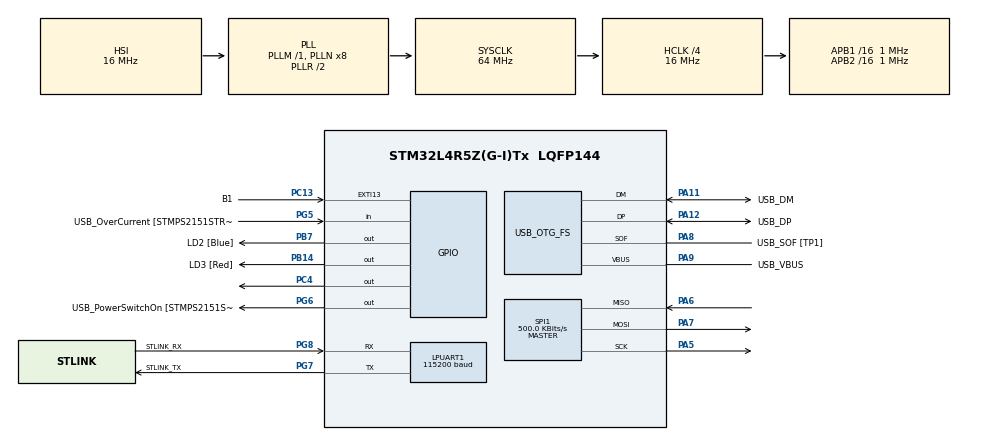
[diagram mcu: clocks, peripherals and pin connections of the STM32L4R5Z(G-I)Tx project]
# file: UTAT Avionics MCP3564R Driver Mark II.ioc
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LPUART1.BaudRate=115200
LPUART1.WordLength=UART_WORDLENGTH_8B
Mcu.Family=STM32L4
Mcu.Name=STM32L4R5Z(G-I)Tx
Mcu.Package=LQFP144
NVIC.PriorityGroup=NVIC_PRIORITYGROUP_4
PA10.GPIO_Label=USB_ID
PA10.Signal=USB_OTG_FS_ID
PA11.GPIO_Label=USB_DM
PA11.Mode=Device_Only
PA11.Signal=USB_OTG_FS_DM
PA12.GPIO_Label=USB_DP
PA12.Mode=Device_Only
PA12.Signal=USB_OTG_FS_DP
PA13\ (JTMS/SWDIO).GPIO_Label=TMS
PA13\ (JTMS/SWDIO).Mode=Trace_Asynchronous_SW
PA13\ (JTMS/SWDIO).Signal=SYS_JTMS-SWDIO
PA14\ (JTCK/SWCLK).GPIO_Label=TCK
PA14\ (JTCK/SWCLK).Mode=Trace_Asynchronous_SW
PA14\ (JTCK/SWCLK).Signal=SYS_JTCK-SWCLK
PA5.Mode=Full_Duplex_Master
PA5.Signal=SPI1_SCK
PA6.Mode=Full_Duplex_Master
PA6.Signal=SPI1_MISO
PA7.Mode=Full_Duplex_Master
PA7.Signal=SPI1_MOSI
PA8.GPIO_Label=USB_SOF [TP1]
PA8.Mode=Activate_SOF_FS
PA8.Signal=USB_OTG_FS_SOF
PA9.GPIO_Label=USB_VBUS
PA9.Mode=Activate_VBUS
PA9.Signal=USB_OTG_FS_VBUS
PB14.GPIO_Label=LD3 [Red]
PB14.Signal=GPIO_Output
PB3\ (JTDO/TRACESWO).GPIO_Label=SWO
PB3\ (JTDO/TRACESWO).Mode=Trace_Asynchronous_SW
PB3\ (JTDO/TRACESWO).Signal=SYS_JTDO-SWO
PB7.GPIO_Label=LD2 [Blue]
PB7.Signal=GPIO_Output
PC13.GPIO_Label=B1
PC13.Signal=GPXTI13
PC14-OSC32_IN\ (PC14).Mode=LSE-External-Oscillator
PC14-OSC32_IN\ (PC14).Signal=RCC_OSC32_IN
PC15-OSC32_OUT\ (PC15).Mode=LSE-External-Oscillator
PC15-OSC32_OUT\ (PC15).Signal=RCC_OSC32_OUT
PC4.Signal=GPIO_Output
PD8.GPIO_Label=STLK_RX [STM32F103CBT6_PA3]
PD8.Signal=USART3_TX
PD9.GPIO_Label=STLK_TX [STM32F103CBT6_PA2]
PD9.Signal=USART3_RX
PG5.GPIO_Label=USB_OverCurrent [STMPS2151STR_FAULT]
PG5.Signal=GPIO_Input
PG6.GPIO_Label=USB_PowerSwitchOn [STMPS2151STR_EN]
PG6.Signal=GPIO_Output
PG7.GPIO_Label=STLINK_TX
PG7.Mode=Asynchronous
PG7.Signal=LPUART1_TX
PG8.GPIO_Label=STLINK_RX
PG8.Mode=Asynchronous
PG8.Signal=LPUART1_RX
PH0-OSC_IN\ (PH0).Signal=RCC_OSC_IN
PH1-OSC_OUT\ (PH1).Signal=RCC_OSC_OUT
ProjectManager.HeapSize=0x200
ProjectManager.StackSize=0x400
ProjectManager.TargetToolchain=STM32CubeIDE
RCC.48MHZClocksFreq_Value=24000000
RCC.ADCFreq_Value=96000000
RCC.AHBCLKDivider=RCC_SYSCLK_DIV4
RCC.AHBFreq_Value=16000000
RCC.APB1CLKDivider=RCC_HCLK_DIV16
RCC.APB1Freq_Value=1000000
RCC.APB1TimFreq_Value=2000000
RCC.APB2CLKDivider=RCC_HCLK_DIV16
RCC.APB2Freq_Value=1000000
RCC.APB2TimFreq_Value=2000000
RCC.CK48CLockSelection=RCC_USBCLKSOURCE_HSI48
RCC.CortexFreq_Value=16000000
RCC.HCLKFreq_Value=16000000
RCC.HSE_VALUE=8000000
RCC.HSI48_VALUE=48000000
RCC.HSI_VALUE=16000000
RCC.MSI_VALUE=4000000
RCC.PLLMUL=RCC_PLL_MUL9
RCC.PLLSAI1N=12
RCC.PLLSourceVirtual=RCC_PLLSOURCE_HSI
RCC.PRESCALERUSB=RCC_USBCLKSOURCE_PLL_DIV1_5
RCC.SYSCLKFreq_VALUE=64000000
RCC.SYSCLKSource=RCC_SYSCLKSOURCE_PLLCLK
RCC.SYSCLKSourceVirtual=RCC_SYSCLKSOURCE_PLLCLK
RCC.USBFreq_Value=48000000
RCC.VCOOutputFreq_Value=128000000
SPI1.CalculateBaudRate=500.0 KBits/s
SPI1.DataSize=SPI_DATASIZE_8BIT
SPI1.Direction=SPI_DIRECTION_2LINES
SPI1.Mode=SPI_MODE_MASTER
SPI1.VirtualType=VM_MASTER
USB_OTG_FS.VirtualMode=Device_Only
board=NUCLEO-L4R5ZI

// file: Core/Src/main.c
/* USER CODE BEGIN Header */
/**
  ******************************************************************************
  * @file           : main.c
  * @brief          : Main program body
  ******************************************************************************
  * @attention
  *
  * Copyright (c) 2025 STMicroelectronics.
  * All rights reserved.
  *
  * This software is licensed under terms that can be found in the LICENSE file
  * in the root directory of this software component.
  * If no LICENSE file comes with this software, it is provided AS-IS.
  *
  ******************************************************************************
  */
/* USER CODE END Header */
#include "main.h"

/* USER CODE BEGIN Includes */
#include "MCP3564R.h"
#include <stdio.h>
#include <string.h>
/* USER CODE END Includes */

UART_HandleTypeDef hlpuart1;

SPI_HandleTypeDef hspi1;

PCD_HandleTypeDef hpcd_USB_OTG_FS;

void SystemClock_Config(void);
static void MX_GPIO_Init(void);
static void MX_LPUART1_UART_Init(void);
static void MX_USB_OTG_FS_PCD_Init(void);
static void MX_SPI1_Init(void);

int main(void)
{

  /* USER CODE BEGIN 1 */
	  int status;
	  uint32_t channelReading = 0;
	  unsigned char tx_buff[100];
  /* USER CODE END 1 */

  /* MCU Configuration--------------------------------------------------------*/

  /* Reset of all peripherals, Initializes the Flash interface and the Systick. */
  HAL_Init();

  /* Configure the system clock */
  SystemClock_Config();

  /* Initialize all configured peripherals */
  MX_GPIO_Init();
  MX_LPUART1_UART_Init();
  MX_USB_OTG_FS_PCD_Init();
  MX_SPI1_Init();
  /* USER CODE BEGIN 2 */
  	// Initially set ~CS pin high
  	HAL_GPIO_WritePin(GPIOC, GPIO_PIN_4, GPIO_PIN_SET);
  	// Initialize MCP3564R
  	status = MCP3564_Init(&hspi1);
  	if(status == HAL_ERROR) {
  		sprintf((char*)tx_buff, "ERROR: MCP3564R failed to initiate\n\r");
  		HAL_UART_Transmit(&hlpuart1, tx_buff, strlen((char*)tx_buff), 1000);
  	}

  /* USER CODE END 2 */

  /* Infinite loop */
  /* USER CODE BEGIN WHILE */
  while (1)
  {
	  // attempts to read channel data
	status = MCP3564_ReadChannel(&channelReading);

	sprintf((char*)tx_buff, "CH0: %d \n\r", channelReading);
	HAL_UART_Transmit(&hlpuart1, tx_buff, strlen((char*)tx_buff), 1000);
    /* USER CODE END WHILE */

  }
}

void SystemClock_Config(void)
{
  RCC_OscInitTypeDef RCC_OscInitStruct = {0};
  RCC_ClkInitTypeDef RCC_ClkInitStruct = {0};

  /** Configure the main internal regulator output voltage
  */
  if (HAL_PWREx_ControlVoltageScaling(PWR_REGULATOR_VOLTAGE_SCALE1) != HAL_OK)
  {
    Error_Handler();
  }

  /** Initializes the RCC Oscillators according to the specified parameters
  * in the RCC_OscInitTypeDef structure.
  */
  RCC_OscInitStruct.OscillatorType = RCC_OSCILLATORTYPE_HSI48|RCC_OSCILLATORTYPE_HSI;
  RCC_OscInitStruct.HSIState = RCC_HSI_ON;
  RCC_OscInitStruct.HSI48State = RCC_HSI48_ON;
  RCC_OscInitStruct.HSICalibrationValue = RCC_HSICALIBRATION_DEFAULT;
  RCC_OscInitStruct.PLL.PLLState = RCC_PLL_ON;
  RCC_OscInitStruct.PLL.PLLSource = RCC_PLLSOURCE_HSI;
  RCC_OscInitStruct.PLL.PLLM = 1;
  RCC_OscInitStruct.PLL.PLLN = 8;
  RCC_OscInitStruct.PLL.PLLP = RCC_PLLP_DIV2;
  RCC_OscInitStruct.PLL.PLLQ = RCC_PLLQ_DIV2;
  RCC_OscInitStruct.PLL.PLLR = RCC_PLLR_DIV2;
  if (HAL_RCC_OscConfig(&RCC_OscInitStruct) != HAL_OK)
  {
    Error_Handler();
  }

  /** Initializes the CPU, AHB and APB buses clocks
  */
  RCC_ClkInitStruct.ClockType = RCC_CLOCKTYPE_HCLK|RCC_CLOCKTYPE_SYSCLK
                              |RCC_CLOCKTYPE_PCLK1|RCC_CLOCKTYPE_PCLK2;
  RCC_ClkInitStruct.SYSCLKSource = RCC_SYSCLKSOURCE_PLLCLK;
  RCC_ClkInitStruct.AHBCLKDivider = RCC_SYSCLK_DIV4;
  RCC_ClkInitStruct.APB1CLKDivider = RCC_HCLK_DIV16;
  RCC_ClkInitStruct.APB2CLKDivider = RCC_HCLK_DIV16;

  if (HAL_RCC_ClockConfig(&RCC_ClkInitStruct, FLASH_LATENCY_0) != HAL_OK)
  {
    Error_Handler();
  }
}

static void MX_LPUART1_UART_Init(void)
{

  hlpuart1.Instance = LPUART1;
  hlpuart1.Init.BaudRate = 115200;
  hlpuart1.Init.WordLength = UART_WORDLENGTH_8B;
  hlpuart1.Init.StopBits = UART_STOPBITS_1;
  hlpuart1.Init.Parity = UART_PARITY_NONE;
  hlpuart1.Init.Mode = UART_MODE_TX_RX;
  hlpuart1.Init.HwFlowCtl = UART_HWCONTROL_NONE;
  hlpuart1.Init.OneBitSampling = UART_ONE_BIT_SAMPLE_DISABLE;
  hlpuart1.Init.ClockPrescaler = UART_PRESCALER_DIV1;
  hlpuart1.AdvancedInit.AdvFeatureInit = UART_ADVFEATURE_NO_INIT;
  hlpuart1.FifoMode = UART_FIFOMODE_DISABLE;
  if (HAL_UART_Init(&hlpuart1) != HAL_OK)
  {
    Error_Handler();
  }
  if (HAL_UARTEx_SetTxFifoThreshold(&hlpuart1, UART_TXFIFO_THRESHOLD_1_8) != HAL_OK)
  {
    Error_Handler();
  }
  if (HAL_UARTEx_SetRxFifoThreshold(&hlpuart1, UART_RXFIFO_THRESHOLD_1_8) != HAL_OK)
  {
    Error_Handler();
  }
  if (HAL_UARTEx_DisableFifoMode(&hlpuart1) != HAL_OK)
  {
    Error_Handler();
  }

}

static void MX_SPI1_Init(void)
{

  /* SPI1 parameter configuration*/
  hspi1.Instance = SPI1;
  hspi1.Init.Mode = SPI_MODE_MASTER;
  hspi1.Init.Direction = SPI_DIRECTION_2LINES;
  hspi1.Init.DataSize = SPI_DATASIZE_8BIT;
  hspi1.Init.CLKPolarity = SPI_POLARITY_LOW;
  hspi1.Init.CLKPhase = SPI_PHASE_1EDGE;
  hspi1.Init.NSS = SPI_NSS_SOFT;
  hspi1.Init.BaudRatePrescaler = SPI_BAUDRATEPRESCALER_2;
  hspi1.Init.FirstBit = SPI_FIRSTBIT_MSB;
  hspi1.Init.TIMode = SPI_TIMODE_DISABLE;
  hspi1.Init.CRCCalculation = SPI_CRCCALCULATION_DISABLE;
  hspi1.Init.CRCPolynomial = 7;
  hspi1.Init.CRCLength = SPI_CRC_LENGTH_DATASIZE;
  hspi1.Init.NSSPMode = SPI_NSS_PULSE_ENABLE;
  if (HAL_SPI_Init(&hspi1) != HAL_OK)
  {
    Error_Handler();
  }

}

static void MX_USB_OTG_FS_PCD_Init(void)
{

  hpcd_USB_OTG_FS.Instance = USB_OTG_FS;
  hpcd_USB_OTG_FS.Init.dev_endpoints = 6;
  hpcd_USB_OTG_FS.Init.speed = PCD_SPEED_FULL;
  hpcd_USB_OTG_FS.Init.phy_itface = PCD_PHY_EMBEDDED;
  hpcd_USB_OTG_FS.Init.Sof_enable = ENABLE;
  hpcd_USB_OTG_FS.Init.low_power_enable = DISABLE;
  hpcd_USB_OTG_FS.Init.lpm_enable = DISABLE;
  hpcd_USB_OTG_FS.Init.battery_charging_enable = ENABLE;
  hpcd_USB_OTG_FS.Init.use_dedicated_ep1 = DISABLE;
  hpcd_USB_OTG_FS.Init.vbus_sensing_enable = ENABLE;
  if (HAL_PCD_Init(&hpcd_USB_OTG_FS) != HAL_OK)
  {
    Error_Handler();
  }

}

static void MX_GPIO_Init(void)
{
  GPIO_InitTypeDef GPIO_InitStruct = {0};

  /* GPIO Ports Clock Enable */
  __HAL_RCC_GPIOC_CLK_ENABLE();
  __HAL_RCC_GPIOH_CLK_ENABLE();
  __HAL_RCC_GPIOA_CLK_ENABLE();
  __HAL_RCC_GPIOB_CLK_ENABLE();
  __HAL_RCC_GPIOD_CLK_ENABLE();
  __HAL_RCC_GPIOG_CLK_ENABLE();
  HAL_PWREx_EnableVddIO2();

  /*Configure GPIO pin Output Level */
  HAL_GPIO_WritePin(GPIOC, GPIO_PIN_4, GPIO_PIN_RESET);

  /*Configure GPIO pin Output Level */
  HAL_GPIO_WritePin(GPIOB, LD3_Pin|LD2_Pin, GPIO_PIN_RESET);

  /*Configure GPIO pin Output Level */
  HAL_GPIO_WritePin(USB_PowerSwitchOn_GPIO_Port, USB_PowerSwitchOn_Pin, GPIO_PIN_RESET);

  /*Configure GPIO pin : B1_Pin */
  GPIO_InitStruct.Pin = B1_Pin;
  GPIO_InitStruct.Mode = GPIO_MODE_IT_RISING;
  GPIO_InitStruct.Pull = GPIO_NOPULL;
  HAL_GPIO_Init(B1_GPIO_Port, &GPIO_InitStruct);

  /*Configure GPIO pin : PC4 */
  GPIO_InitStruct.Pin = GPIO_PIN_4;
  GPIO_InitStruct.Mode = GPIO_MODE_OUTPUT_PP;
  GPIO_InitStruct.Pull = GPIO_NOPULL;
  GPIO_InitStruct.Speed = GPIO_SPEED_FREQ_LOW;
  HAL_GPIO_Init(GPIOC, &GPIO_InitStruct);

  /*Configure GPIO pins : LD3_Pin LD2_Pin */
  GPIO_InitStruct.Pin = LD3_Pin|LD2_Pin;
  GPIO_InitStruct.Mode = GPIO_MODE_OUTPUT_PP;
  GPIO_InitStruct.Pull = GPIO_NOPULL;
  GPIO_InitStruct.Speed = GPIO_SPEED_FREQ_LOW;
  HAL_GPIO_Init(GPIOB, &GPIO_InitStruct);

  /*Configure GPIO pins : STLK_RX_Pin STLK_TX_Pin */
  GPIO_InitStruct.Pin = STLK_RX_Pin|STLK_TX_Pin;
  GPIO_InitStruct.Mode = GPIO_MODE_AF_PP;
  GPIO_InitStruct.Pull = GPIO_NOPULL;
  GPIO_InitStruct.Speed = GPIO_SPEED_FREQ_VERY_HIGH;
  GPIO_InitStruct.Alternate = GPIO_AF7_USART3;
  HAL_GPIO_Init(GPIOD, &GPIO_InitStruct);

  /*Configure GPIO pin : USB_OverCurrent_Pin */
  GPIO_InitStruct.Pin = USB_OverCurrent_Pin;
  GPIO_InitStruct.Mode = GPIO_MODE_INPUT;
  GPIO_InitStruct.Pull = GPIO_NOPULL;
  HAL_GPIO_Init(USB_OverCurrent_GPIO_Port, &GPIO_InitStruct);

  /*Configure GPIO pin : USB_PowerSwitchOn_Pin */
  GPIO_InitStruct.Pin = USB_PowerSwitchOn_Pin;
  GPIO_InitStruct.Mode = GPIO_MODE_OUTPUT_PP;
  GPIO_InitStruct.Pull = GPIO_NOPULL;
  GPIO_InitStruct.Speed = GPIO_SPEED_FREQ_LOW;
  HAL_GPIO_Init(USB_PowerSwitchOn_GPIO_Port, &GPIO_InitStruct);

}

void Error_Handler(void)
{
  __disable_irq();
  while (1)
  {
  }
}
